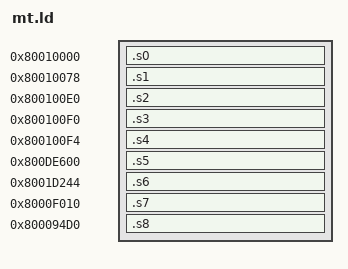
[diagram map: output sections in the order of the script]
SECTIONS {  .s0 0x80010000 : { KEEP(mtcore.o(.rodata.vmtab9)) . = ALIGN(4); }  .s1 0x80010078 : { KEEP(mtcore.o(.rodata.vmtab8)) . = ALIGN(4); }  .s2 0x800100e0 : { KEEP(mtcore.o(.text.mt_sel_j)) . = ALIGN(4); }  .s3 0x800100f0 : { KEEP(mtcore.o(.bss.vsmbyte)) . = ALIGN(4); }  .s4 0x800100f4 : { KEEP(mtcore.o(.text.route_v)) KEEP(mtcore.o(.text.vs_body)) KEEP(mtcore.o(.text.kc.point)) KEEP(mtcore.o(.text.mt_mshsel)) KEEP(mtcore.o(.text.kc.fight)) KEEP(mtcore.o(.text.mt_mask_v)) KEEP(mtcore.o(.text.mt_tick)) KEEP(mtcore.o(.text.mt_mask_stock)) . = ALIGN(4); }  .s5 0x800de600 : { KEEP(mtcore.o(.text.vsui)) KEEP(mtcore.o(.rodata.vsui.kc)) . = ALIGN(4); }  .s6 0x8001d244 : { KEEP(mtcore.o(.bss.kz.mtv)) KEEP(mtcore.o(.bss.kz.ssec)) . = ALIGN(4); }  .s7 0x8000f010 : {  . = ALIGN(4); }  .s8 0x800094d0 : {  . = ALIGN(4); } /DISCARD/ : { *(*) } }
